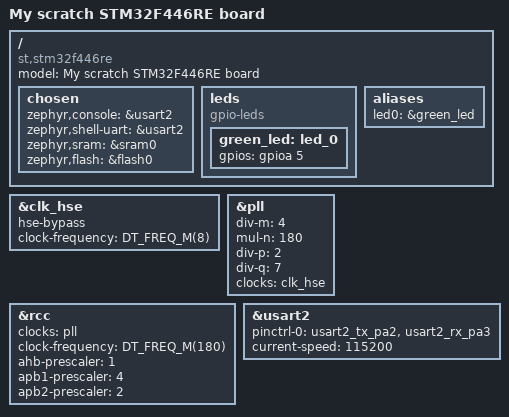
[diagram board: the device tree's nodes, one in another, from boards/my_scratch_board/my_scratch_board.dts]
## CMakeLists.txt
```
cmake_minimum_required(VERSION 3.20.0)


list(APPEND BOARD_ROOT ${CMAKE_CURRENT_SOURCE_DIR})
find_package(Zephyr REQUIRED)
project(my_zephyr_app)

target_sources(app PRIVATE src/main.cpp)
target_include_directories(app PRIVATE drivers/our_driver)

add_subdirectory(drivers/our_driver)
```

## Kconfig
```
menuconfig LED_SUBSYSTEM
    bool "LED Subsystem"
    default y
    help
      Enable the LED subsystem and its configuration options.

if LED_SUBSYSTEM

menu "LED blink sleep time"

choice
    prompt "LED blink sleep time"
    default BLINK_SLEEP_TIME_1000MS

config BLINK_SLEEP_TIME_250MS
    bool "250 ms (fast)"

config BLINK_SLEEP_TIME_500MS
    bool "500 ms"

config BLINK_SLEEP_TIME_1000MS
    bool "1s (medium)"

config BLINK_SLEEP_TIME_2000MS
    bool "2s (slow)"

endchoice

config BLINK_SLEEP_TIME_MS
    int
    default 250 if BLINK_SLEEP_TIME_250MS
    default 500 if BLINK_SLEEP_TIME_500MS
    default 1000 if BLINK_SLEEP_TIME_1000MS
    default 2000 if BLINK_SLEEP_TIME_2000MS

endmenu


menuconfig LED_ADVANCED_SETTINGS
    bool "Advanced LED settings"

if LED_ADVANCED_SETTINGS

config LED_BRIGHTNESS
    int "LED brightness (0-100)"
    range 0 100
    default 100

config LED_FADE_DURATION
    int "LED fade duration (ms)"
    range 0 5000
    default 500

menu "Expert settings"
    visible if LED_ADVANCED_SETTINGS

config LED_DEBUG
    bool "Enable LED debugging"

config LED_CUSTOM_BLINK_PATTERN
    bool "Custom blink pattern"

endmenu

endif 

endif 

source "Kconfig.zephyr"
```

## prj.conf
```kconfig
CONFIG_GPIO=y
CONFIG_LOG=y
CONFIG_OUR_DRIVER=y
CONFIG_SENSOR=y

CONFIG_SHELL=y
```

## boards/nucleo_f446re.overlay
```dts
/ {
	our_driver: our_driver {
		compatible = "our,driver";
		gpios = <&gpioa 5 GPIO_ACTIVE_HIGH>;
		status = "okay";
	};
};
```

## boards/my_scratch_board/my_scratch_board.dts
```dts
/dts-v1/;
#include <st/f4/stm32f446Xe.dtsi>
#include <st/f4/stm32f446r(c-e)tx-pinctrl.dtsi>
#include <zephyr/dt-bindings/gpio/gpio.h>

/ {
    model = "My scratch STM32F446RE board";
    compatible = "st,stm32f446re";

    chosen {
        zephyr,console = &usart2;
        zephyr,shell-uart = &usart2;
        zephyr,sram = &sram0;
        zephyr,flash = &flash0;
    };

    leds {
        compatible = "gpio-leds";
        green_led: led_0 {
            gpios = <&gpioa 5 GPIO_ACTIVE_HIGH>;
        };
    };

    aliases {
        led0 = &green_led;
    };
};

&clk_hse {
    hse-bypass;
    clock-frequency = <DT_FREQ_M(8)>;
    status = "okay";
};

&pll {
    div-m = <4>;
    mul-n = <180>;
    div-p = <2>;
    div-q = <7>;
    clocks = <&clk_hse>;
    status = "okay";
};

&rcc {
    clocks = <&pll>;
    clock-frequency = <DT_FREQ_M(180)>;
    ahb-prescaler = <1>;
    apb1-prescaler = <4>;
    apb2-prescaler = <2>;
};

&usart2 {
    pinctrl-0 = <&usart2_tx_pa2 &usart2_rx_pa3>;
    pinctrl-names = "default";
    current-speed = <115200>;
    status = "okay";
};
```

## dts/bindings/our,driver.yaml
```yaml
description: Simple LED-as-sensor driver
compatible: "our,driver"
include: base.yaml
properties:
  gpios:
    type: phandle-array
    required: true
```

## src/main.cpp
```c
#include <zephyr/kernel.h>

int main(void)
{

	return 0;
}
```
